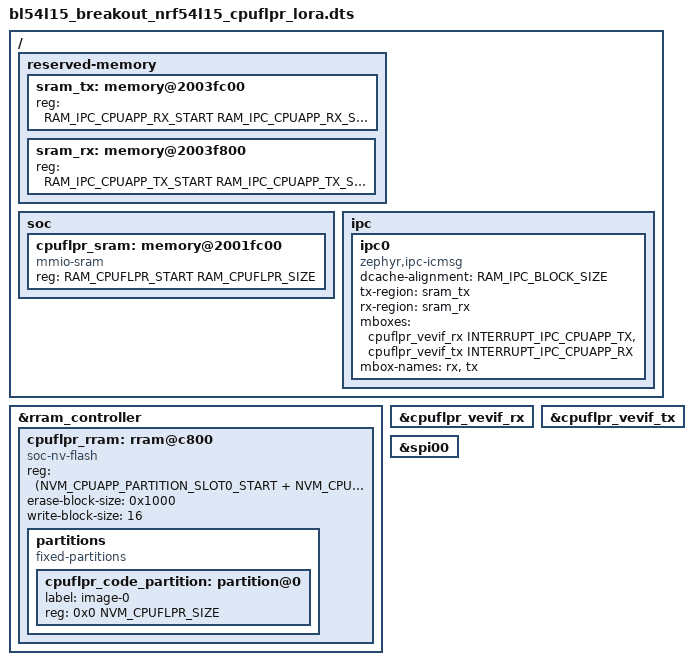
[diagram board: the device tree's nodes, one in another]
/*
 * Copyright (c) 2025 Jamie M.
 *
 * All right reserved. This code is NOT apache or FOSS/copyleft licensed.
 */

#include "bl54l15_breakout_nrf54l15_cpuflpr.dts"
#include "bl54l15_breakout_lora_common.dtsi"

/delete-node/ &cpuflpr_sram;
/delete-node/ &cpuflpr_code_partition;
/delete-node/ &cpuflpr_rram;

/ {
	reserved-memory {
		#address-cells = <1>;
		#size-cells = <1>;
		ranges;

		sram_tx: memory@2003fc00 {
			reg = <RAM_IPC_CPUAPP_RX_START RAM_IPC_CPUAPP_RX_SIZE>;
		};

		sram_rx: memory@2003f800 {
			reg = <RAM_IPC_CPUAPP_TX_START RAM_IPC_CPUAPP_TX_SIZE>;
		};
	};

	soc {
		cpuflpr_sram: memory@2001fc00 {
			compatible = "mmio-sram";
			reg = <RAM_CPUFLPR_START RAM_CPUFLPR_SIZE>;
			#address-cells = <1>;
			#size-cells = <1>;
			ranges = <0x0 RAM_CPUFLPR_START RAM_CPUFLPR_SIZE>;
		};
	};

	ipc {
		ipc0: ipc0 {
			compatible = "zephyr,ipc-icmsg";
			dcache-alignment = <RAM_IPC_BLOCK_SIZE>;
			tx-region = <&sram_tx>;
			rx-region = <&sram_rx>;
			mboxes = <&cpuflpr_vevif_rx INTERRUPT_IPC_CPUAPP_TX>, <&cpuflpr_vevif_tx INTERRUPT_IPC_CPUAPP_RX>;
			mbox-names = "rx", "tx";
			status = "okay";
		};
	};
};

&rram_controller {
	cpuflpr_rram: rram@c800 {
		compatible = "soc-nv-flash";
		reg = <(NVM_CPUAPP_PARTITION_SLOT0_START + NVM_CPUFLPR_OFFSET) NVM_CPUFLPR_SIZE>;
		erase-block-size = <0x1000>;
		write-block-size = <16>;

		partitions {
			compatible = "fixed-partitions";
			#address-cells = <1>;
			#size-cells = <1>;

			cpuflpr_code_partition: partition@0 {
				label = "image-0";
				reg = <0x0 NVM_CPUFLPR_SIZE>;
			};
		};
	};
};

&cpuflpr_sram {
	reg = <RAM_CPUFLPR_START RAM_CPUFLPR_SIZE>;
	ranges = <0x0 RAM_CPUFLPR_START RAM_CPUFLPR_SIZE>;
};

&cpuflpr_vevif_rx {
	status = "okay";
};

&cpuflpr_vevif_tx {
	status = "okay";
};

&spi00 {
	status = "okay";
};
